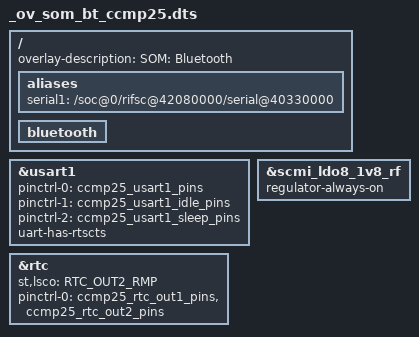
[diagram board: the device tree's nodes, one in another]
/*
 * Copyright 2024 Digi International Inc.
 *
 * Permission to use, copy, modify, and/or distribute this software for any
 * purpose with or without fee is hereby granted, provided that the above
 * copyright notice and this permission notice appear in all copies.
 * THE SOFTWARE IS PROVIDED "AS IS" AND THE AUTHOR DISCLAIMS ALL WARRANTIES
 * WITH REGARD TO THIS SOFTWARE INCLUDING ALL IMPLIED WARRANTIES OF
 * MERCHANTABILITY AND FITNESS. IN NO EVENT SHALL THE AUTHOR BE LIABLE FOR
 * ANY SPECIAL, DIRECT, INDIRECT, OR CONSEQUENTIAL DAMAGES OR ANY DAMAGES
 * WHATSOEVER RESULTING FROM LOSS OF USE, DATA OR PROFITS, WHETHER IN AN
 * ACTION OF CONTRACT, NEGLIGENCE OR OTHER TORTIOUS ACTION, ARISING OUT OF
 * OR IN CONNECTION WITH THE USE OR PERFORMANCE OF THIS SOFTWARE.
 */

#include <dt-bindings/gpio/gpio.h>
#include <dt-bindings/rtc/rtc-stm32.h>

/dts-v1/;
/plugin/;

/ {
	fragment@0 {
		target-path = "/";
		__overlay__ {
			overlay-description = "SOM: Bluetooth";
			aliases {
				serial1 = "/soc@0/rifsc@42080000/serial@40330000"; /* Bluetooth */
			};
			bluetooth {
				/* U-Boot will fill in the MAC address here */
			};
		};
	};

	/* Enable USART1 (Bluetooth) */
	fragment@1 {
		target = <&usart1>;
		__overlay__ {
			pinctrl-names = "default", "idle", "sleep";
			pinctrl-0 = <&ccmp25_usart1_pins>;
			pinctrl-1 = <&ccmp25_usart1_idle_pins>;
			pinctrl-2 = <&ccmp25_usart1_sleep_pins>;
			uart-has-rtscts;
			status = "okay";

			/*
			 * Currently the early FW is not supported by the driver, so we use
			 * the generic HCI_UART support.
			 */
//			cyw55512_bt: cyw55512-bt {
//				shutdown-gpios = <&gpioz 5 GPIO_ACTIVE_HIGH>; /* BT_REG_EN */
//				compatible = "brcm,bcm43438-bt";
//				max-speed = <3000000>;
//				vbat-supply = <&scmi_v3v3>;
//				vddio-supply = <&scmi_ldo8_1v8_rf>;
//			};
		};
	};

	/* Enable External 32kHz Low-Power Oscillator */
	fragment@2 {
		target = <&rtc>;
		__overlay__ {
			st,lsco = <RTC_OUT2_RMP>;
			pinctrl-0 = <&ccmp25_rtc_out1_pins &ccmp25_rtc_out2_pins>;
			pinctrl-names = "default";
		};
	};

	/*
	 * This regulator needs to be enabled by the driver.
	 * Since the driver is not currently in use, enable the regulator always.
	 */
	fragment@3 {
		target = <&scmi_ldo8_1v8_rf>;
		__overlay__ {
			regulator-always-on;
		};
	};
};
